# MCXA133 register map
Vendor: nxp.com; File version: 1.0
CPU: CM33 r2p0, little endian, no MPU, no FPU, VTOR, 3 interrupt priority bits
Registers are 32-bit, read-write, reset 0x0 unless marked. A register's access mark holds for its fields unless they carry their own. Offsets are from the block's base; [hi:lo] are bit positions; {n}, {i} and the like mark numbered series.

## DBGMAILBOX — DBGMB
Base 0x40101000
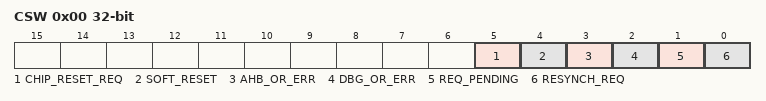
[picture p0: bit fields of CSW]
0x00 CSW — Command and Status Word
  [5] CHIP_RESET_REQ — Chip Reset Request
  [4] SOFT_RESET
  [3] AHB_OR_ERR — AHB Overrun Error
    0=NO_AHB_OVERRUN_ERR (No AHB Overrun Error); 1=AHB_OVERRUN_ERR (AHB Overrun Error. An AHB overrun occurred.)
  [2] DBG_OR_ERR — DBGMB Overrun Error
    0=NO_OVERRUN_ERR (No DBGMB Overrun error); 1=OVERRUN_ERR (DBGMB overrun error. A DBGMB overrun occurred.)
  [1] REQ_PENDING — Request Pending
    0=NO_REQUEST_PENDING; 1=REQUEST_PENDING (Request for resynchronization pending)
  [0] RESYNCH_REQ — Resynchronization Request
    0=NO_REQUEST; 1=REQUEST (Request for resynchronization)
0x04 REQUEST — Request Value
0x08 RETURN — Return Value
  [31:0] RET
0xFC ID ro reset 0x2A0000 — Identification
  [31:0] ID — Identification Value

## GPIO0 — GPIO
Base 0x40102000
Same registers: GPIO1 0x40103000, GPIO2 0x40104000, GPIO3 0x40105000
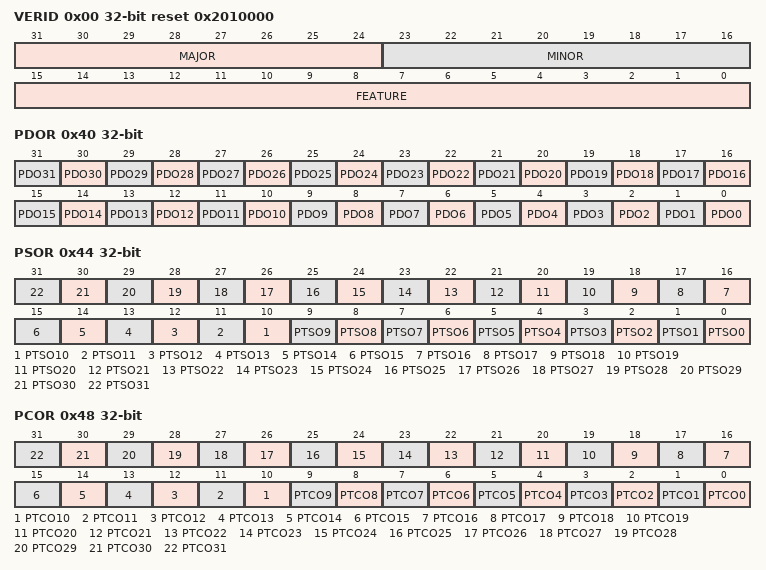
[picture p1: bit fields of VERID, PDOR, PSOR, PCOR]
0x00 VERID ro reset 0x2010000 — Version ID
  [31:24] MAJOR — Major Version Number
  [23:16] MINOR — Minor Version Number
  [15:0] FEATURE — Feature Specification Number
    0=Basic implementation; 1=Protection registers implemented
0x04 PARAM ro reset 0x1 — Parameter
  [3:0] IRQNUM — Interrupt Number
0x40 PDOR — Port Data Output
  [all] fields
    0=pdo0 (Logic level 0); 1=pdo1 (Logic level 1)
  [n] PDO{n} (n=0..31) — Port Data Output
0x44 PSOR — Port Set Output
  [all] fields
    0=ptso0 (No change); 1=ptso1 (Corresponding field in PDOR becomes 1)
  [n] PTSO{n} (n=0..31) — Port Set Output
0x48 PCOR — Port Clear Output
  [all] fields
    0=ptco0 (No change); 1=ptco1 (Corresponding field in PDOR becomes 0)
  [n] PTCO{n} (n=0..31) — Port Clear Output
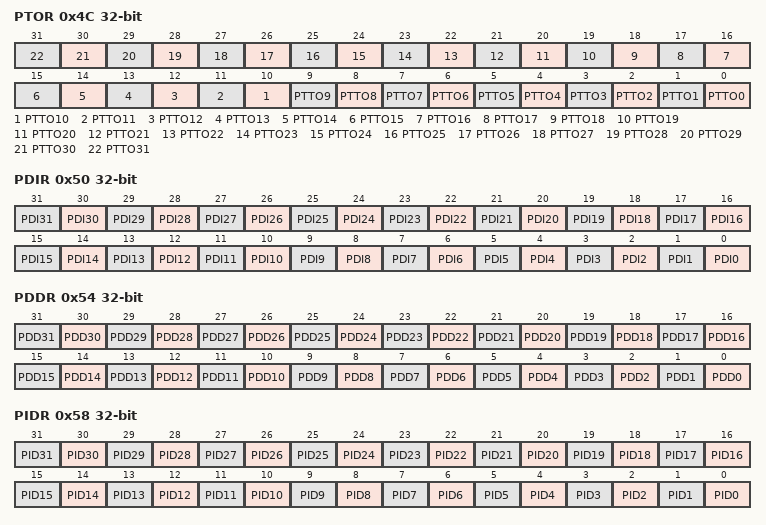
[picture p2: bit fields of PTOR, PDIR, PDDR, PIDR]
0x4C PTOR — Port Toggle Output
  [all] fields
    0=ptto0 (No change); 1=ptto1 (Set to the inverse of its current logic state)
  [n] PTTO{n} (n=0..31) — Port Toggle Output
0x50 PDIR ro — Port Data Input
  [all] fields
    0=pdi0 (Logic 0); 1=pdi1 (Logic 1)
  [n] PDI{n} (n=0..31) — Port Data Input
0x54 PDDR — Port Data Direction
  [all] fields
    0=pdd0 (Input); 1=pdd1 (Output)
  [n] PDD{n} (n=0..31) — Port Data Direction
0x58 PIDR — Port Input Disable
  [all] fields
    0=pid0 (Configured for general-purpose input); 1=pid1 (Disabled for general-purpose input)
  [n] PID{n} (n=0..31) — Port Input Disable
{0x60+i} PDR[{i}] (i=0..31) 8-bit — Pin Data
  [0] PD — Pin Data (I/O)
    0=Logic zero; 1=Logic one
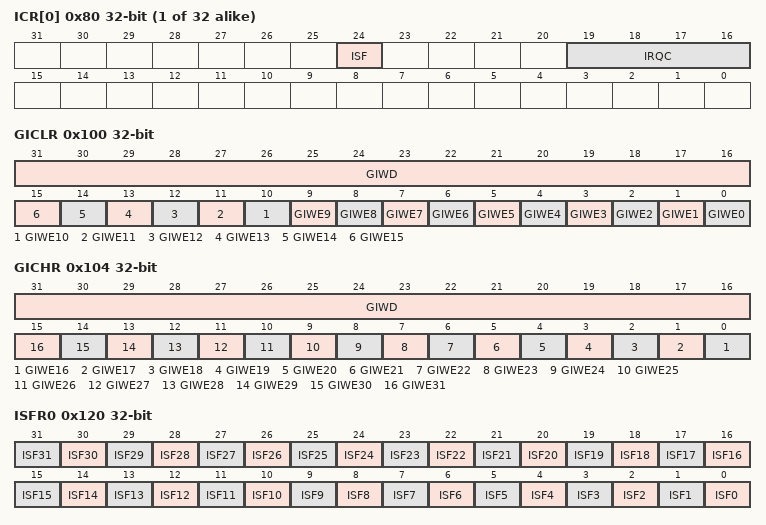
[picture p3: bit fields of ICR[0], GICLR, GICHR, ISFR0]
{0x80+4i} ICR[{i}] (i=0..31) — Interrupt Control index
  [24] ISF write-1-clears — Interrupt Status Flag
    on read: 0=Not detected; 1=Detected
  [19:16] IRQC — Interrupt Configuration
    0=ISF is disabled; 1=ISF and DMA request on rising edge; 2=ISF and DMA request on falling edge; 3=ISF and DMA request on either edge; 5=ISF sets on rising edge; 6=ISF sets on falling edge; 7=ISF sets on either edge; 8=ISF and interrupt when logic 0; 9=ISF and interrupt on rising edge; 10=ISF and interrupt on falling edge; 11=ISF and Interrupt on either edge; 12=ISF and interrupt when logic 1; 13=Enable active-high trigger output; ISF on rising edge (pin state is ORed with other enabled triggers to generate the output trigger for use by other peripherals); 14=Enable active-low trigger output; ISF on falling edge (pin state is inverted and ORed with other enabled triggers to generate the output trigger for use by other peripherals)
0x100 GICLR — Global Interrupt Control Low
  [31:16] GIWD — Global Interrupt Write Data
  [n] GIWE{n} (n=0..15) — Global Interrupt Write Enable
    0=giwe0 (Not updated); 1=giwe1 (Updated)
0x104 GICHR — Global Interrupt Control High
  [31:16] GIWD — Global Interrupt Write Data
  [n-16] GIWE{n} (n=16..31) — Global Interrupt Write Enable
    0=giwe0 (Not updated.); 1=giwe1 (Updated)
0x120 ISFR0 write-1-clears — Interrupt Status Flag
  [all] fields
    on read: 0=isf0 (Not detected); 1=isf1 (Detected)
  [n] ISF{n} write-1-clears (n=0..31) — Interrupt Status Flag
